VERSION "HSCAN2"

NS_ :

BS_:

BU_: IPC MAB

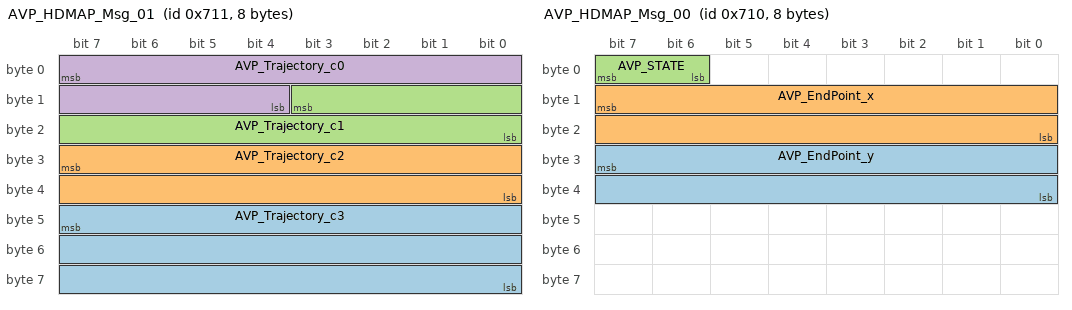
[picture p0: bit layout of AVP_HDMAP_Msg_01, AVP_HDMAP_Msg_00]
BO_ 1809 AVP_HDMAP_Msg_01: 8 IPC
 SG_ AVP_Trajectory_c3 : 47|24@0+ (1E-009,-0.008388608) [-0.008388608|0.008388607] "" Vector__XXX
 SG_ AVP_Trajectory_c2 : 31|16@0+ (1E-006,-0.032768) [-0.032768|0.032767] "" Vector__XXX
 SG_ AVP_Trajectory_c1 : 11|12@0+ (0.0009,-1.8432) [-1.8432|1.8423] "" Vector__XXX
 SG_ AVP_Trajectory_c0 : 7|12@0+ (0.01,-20.48) [-20.48|20.47] "" Vector__XXX

BO_ 1808 AVP_HDMAP_Msg_00: 8 IPC
 SG_ AVP_EndPoint_y : 31|16@0+ (0.01,-327.68) [-327.68|327.67] "" Vector__XXX
 SG_ AVP_EndPoint_x : 15|16@0+ (0.01,-327.68) [-327.68|327.67] "" Vector__XXX
 SG_ AVP_STATE : 7|2@0+ (1,0) [0|3] "" Vector__XXX

BA_DEF_  "BaudRate" FLOAT 1000 1000000;
BA_DEF_ SG_  "GenSigStartValue" INT -9.22337203685478E+018 1.84467440737096E+019;
BA_DEF_DEF_  "BaudRate" 1000;
BA_DEF_DEF_  "GenSigStartValue" 0;
BA_ "BaudRate" 500000;
BA_ "GenSigStartValue" SG_ 1809 AVP_Trajectory_c3 8388608;
BA_ "GenSigStartValue" SG_ 1809 AVP_Trajectory_c2 32768;
BA_ "GenSigStartValue" SG_ 1809 AVP_Trajectory_c1 3048;
BA_ "GenSigStartValue" SG_ 1809 AVP_Trajectory_c0 2048;
BA_ "GenSigStartValue" SG_ 1808 AVP_EndPoint_y 32768;
BA_ "GenSigStartValue" SG_ 1808 AVP_EndPoint_x 32768;
